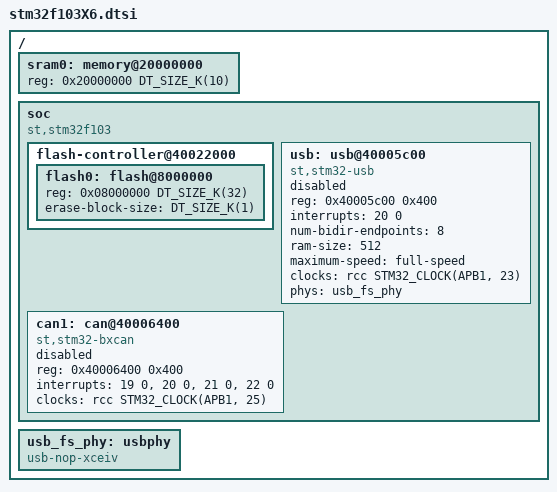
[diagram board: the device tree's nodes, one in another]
/*
 * SPDX-FileCopyrightText: Copyright The Zephyr Project Contributors
 *
 * SPDX-License-Identifier: Apache-2.0
 */
#include <st/f1/stm32f1.dtsi>

/ {
	sram0: memory@20000000 {
		reg = <0x20000000 DT_SIZE_K(10)>;
	};

	soc {
		compatible = "st,stm32f103", "st,stm32f1", "simple-bus";

		flash-controller@40022000 {
			flash0: flash@8000000 {
				reg = <0x08000000 DT_SIZE_K(32)>;
				ranges = <0 0x8000000 DT_SIZE_K(32)>;
				erase-block-size = <DT_SIZE_K(1)>;
			};
		};

		usb: usb@40005c00 {
			compatible = "st,stm32-usb";
			reg = <0x40005c00 0x400>;
			interrupts = <20 0>;
			interrupt-names = "usb";
			num-bidir-endpoints = <8>;
			ram-size = <512>;
			maximum-speed = "full-speed";
			status = "disabled";
			clocks = <&rcc STM32_CLOCK(APB1, 23)>;
			phys = <&usb_fs_phy>;
		};

		can1: can@40006400 {
			compatible = "st,stm32-bxcan";
			reg = <0x40006400 0x400>;
			interrupts = <19 0>, <20 0>, <21 0>, <22 0>;
			interrupt-names = "TX", "RX0", "RX1", "SCE";
			clocks = <&rcc STM32_CLOCK(APB1, 25)>;
			status = "disabled";
		};
	};

	usb_fs_phy: usbphy {
		compatible = "usb-nop-xceiv";
		#phy-cells = <0>;
	};
};
